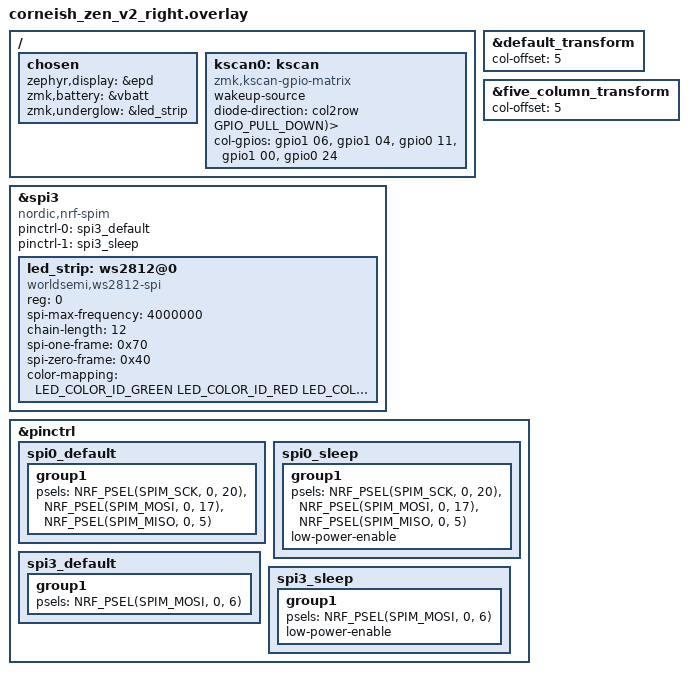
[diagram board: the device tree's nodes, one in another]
/*
*
* Copyright (c) 2021 Darryl deHaan
* SPDX-License-Identifier: MIT
*
*/
#include "corneish_zen.dtsi"
#include <dt-bindings/led/led.h>


/{
    chosen {
        zephyr,display = &epd;
        zmk,battery = &vbatt;
        zmk,underglow = &led_strip;
    };

    kscan0: kscan {
        compatible = "zmk,kscan-gpio-matrix";
 wakeup-source;
        diode-direction = "col2row";
        row-gpios
            , <&gpio1 11 (GPIO_ACTIVE_HIGH | GPIO_PULL_DOWN)>
            , <&gpio1 0 (GPIO_ACTIVE_HIGH | GPIO_PULL_DOWN)>
            , <&gpio0 9 (GPIO_ACTIVE_HIGH | GPIO_PULL_DOWN)>
            ;

        col-gpios
            =<&gpio1 06 GPIO_ACTIVE_HIGH>
			, <&gpio1 04 GPIO_ACTIVE_HIGH>
            , <&gpio0 11 GPIO_ACTIVE_HIGH>
            , <&gpio1 00 GPIO_ACTIVE_HIGH>
            , <&gpio0 24 GPIO_ACTIVE_HIGH>
            ;
    };  
};
&default_transform {
    col-offset = <5>;
};

&five_column_transform {
    col-offset = <5>;
};
//&kscan0 {
 //   col-gpios
  //      = <&gpio1 06 GPIO_ACTIVE_HIGH>
			, <&gpio1 04 GPIO_ACTIVE_HIGH>
            , <&gpio0 11 GPIO_ACTIVE_HIGH>
            , <&gpio1 00 GPIO_ACTIVE_HIGH>
            , <&gpio0 24 GPIO_ACTIVE_HIGH>
            ;
    //    ;
//};
&spi3 {
    compatible = "nordic,nrf-spim";
    status = "okay";

    pinctrl-0 = <&spi3_default>;
    pinctrl-1 = <&spi3_sleep>;
    pinctrl-names = "default", "sleep";

    led_strip: ws2812@0 {
        compatible = "worldsemi,ws2812-spi";

        /* SPI */
        reg = <0>; /* ignored, but necessary for SPI bindings */
        spi-max-frequency = <4000000>;

        /* WS2812 */
        chain-length = <12>; /* 40 keys have underglow at the moment */
        spi-one-frame = <0x70>;
        spi-zero-frame = <0x40>;

        color-mapping = <LED_COLOR_ID_GREEN LED_COLOR_ID_RED LED_COLOR_ID_BLUE>;
    };
};

&pinctrl {
    spi0_default: spi0_default {
        group1 {
            psels = <NRF_PSEL(SPIM_SCK, 0, 20)>,
                <NRF_PSEL(SPIM_MOSI, 0, 17)>,
                <NRF_PSEL(SPIM_MISO, 0, 5)>;
        };
    };

    spi0_sleep: spi0_sleep {
        group1 {
            psels = <NRF_PSEL(SPIM_SCK, 0, 20)>,
                <NRF_PSEL(SPIM_MOSI, 0, 17)>,
                <NRF_PSEL(SPIM_MISO, 0, 5)>;
            low-power-enable;
        };
    };
    spi3_default: spi3_default {
        group1 {
            psels = <NRF_PSEL(SPIM_MOSI, 0, 6)>; // WS2812_VEXT_DATA
        };
    };

    spi3_sleep: spi3_sleep {
        group1 {
            psels = <NRF_PSEL(SPIM_MOSI, 0, 6)>;
            low-power-enable;
        };
    };
};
